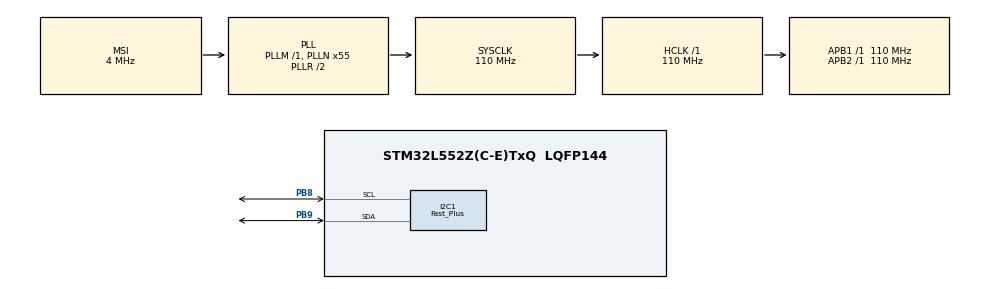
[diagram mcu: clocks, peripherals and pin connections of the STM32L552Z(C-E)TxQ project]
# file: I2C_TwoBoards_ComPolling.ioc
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I2C1.AddressingMode=I2C_ADDRESSINGMODE_10BIT
I2C1.Analog_Filter=I2C_ANALOGFILTER_ENABLE
I2C1.DualAddressMode=I2C_DUALADDRESS_DISABLE
I2C1.GeneralCallMode=I2C_GENERALCALL_DISABLE
I2C1.I2C_Coeff_DF=0
I2C1.I2C_Fall_Time=2
I2C1.I2C_Rise_Time=26
I2C1.I2C_Speed_Mode=I2C_Fast_Plus
I2C1.NoStretchMode=I2C_NOSTRETCH_DISABLE
I2C1.OwnAddress=I2C_ADDRESS
I2C1.Speed=1000
I2C1.Timing=0x00801644
Mcu.Family=STM32L5
Mcu.Name=STM32L552Z(C-E)TxQ
Mcu.Package=LQFP144
Mcu.UserConstants=I2C_ADDRESS,0x30F
NVIC.PriorityGroup=NVIC_PRIORITYGROUP_3
PB8.GPIO_Pu=GPIO_PULLUP
PB8.Mode=I2C
PB8.Signal=I2C1_SCL
PB9.GPIO_Pu=GPIO_PULLUP
PB9.Mode=I2C
PB9.Signal=I2C1_SDA
ProjectManager.HeapSize=0x200
ProjectManager.StackSize=0x400
ProjectManager.TargetToolchain=EWARM V8.32
RCC.ADCCLockSelection=RCC_ADCCLKSOURCE_SYSCLK
RCC.ADCFreq_Value=110000000
RCC.AHBFreq_Value=110000000
RCC.APB1Freq_Value=110000000
RCC.APB1TimFreq_Value=110000000
RCC.APB2Freq_Value=110000000
RCC.APB2TimFreq_Value=110000000
RCC.CK48CLockSelection=RCC_USBCLKSOURCE_MSI
RCC.CortexFreq_Value=110000000
RCC.DATA_CACHE_ENABLE=0
RCC.HCLKFreq_Value=110000000
RCC.HSE_VALUE=16000000
RCC.HSI48_VALUE=48000000
RCC.HSI_VALUE=16000000
RCC.I2C1CLockSelection=RCC_I2C1CLKSOURCE_SYSCLK
RCC.I2C3CLockSelection=RCC_I2C3CLKSOURCE_HSI
RCC.INSTRUCTION_CACHE_ENABLE=0
RCC.LPTIM1CLockSelectionVirtual=RCC_LPTIM1CLKSOURCE_LSE
RCC.LSE_VALUE=32768
RCC.MSI_VALUE=4000000
RCC.PLLN=55
RCC.PLLSAI1N=24
RCC.RTCClockSelection=RCC_RTCCLKSOURCE_LSE
RCC.SYSCLKFreq_VALUE=110000000
RCC.SYSCLKSource=RCC_SYSCLKSOURCE_PLLCLK
RCC.USBFreq_Value=4000000
RCC.VCOOutputFreq_Value=220000000
VP_ICACHE_VS_ICACHE.Mode=DirectMappedCache
VP_PWR_VS_DBSignals.Mode=DisableDeadBatterySignals
board=custom

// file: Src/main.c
/* USER CODE BEGIN Header */
/**
  ******************************************************************************
  * @file    I2C/I2C_TwoBoards_ComPolling/Src/main.c
  * @author  MCD Application Team
  * @brief   This sample code shows how to use STM32L5xx I2C HAL API to transmit
  *          and receive a data buffer with a communication process based on
  *          Polling transfer.
  *          The communication is done using 2 Boards.
  ******************************************************************************
  * @attention
  *
  * Copyright (c) 2019 STMicroelectronics.
  * All rights reserved.
  *
  * This software is licensed under terms that can be found in the LICENSE file
  * in the root directory of this software component.
  * If no LICENSE file comes with this software, it is provided AS-IS.
  *
  ******************************************************************************
  */
/* USER CODE END Header */
#include "main.h"

/* USER CODE BEGIN PD */
/* Uncomment this line to use the board as master, if not it is used as slave */
//#define MASTER_BOARD
/* USER CODE END PD */

I2C_HandleTypeDef hi2c1;

/* USER CODE BEGIN PV */
/* Private variables ---------------------------------------------------------*/
/* Buffer used for transmission */
uint8_t aTxBuffer[] = " ****I2C_TwoBoards communication based on Polling****  ****I2C_TwoBoards communication based on Polling****  ****I2C_TwoBoards communication based on Polling**** ";

/* Buffer used for reception */
uint8_t aRxBuffer[RXBUFFERSIZE];
/* USER CODE END PV */

void SystemClock_Config(void);
static void MX_GPIO_Init(void);
static void MX_ICACHE_Init(void);
static void MX_I2C1_Init(void);
/* USER CODE BEGIN PFP */
/* Private function prototypes -----------------------------------------------*/
static uint16_t Buffercmp(uint8_t *pBuffer1, uint8_t *pBuffer2, uint16_t BufferLength);

/* USER CODE END PFP */

int main(void)
{

  /* USER CODE BEGIN 1 */
  /* STM32L5xx HAL library initialization:
       - Systick timer is configured by default as source of time base, but user
         can eventually implement his proper time base source (a general purpose
         timer for example or other time source), keeping in mind that Time base
         duration should be kept 1ms since PPP_TIMEOUT_VALUEs are defined and
         handled in milliseconds basis.
       - Set NVIC Group Priority to 3
       - Low Level Initialization
     */
  /* USER CODE END 1 */

  /* MCU Configuration--------------------------------------------------------*/

  /* Reset of all peripherals, Initializes the Flash interface and the Systick. */
  HAL_Init();

  /* Configure the system clock */
  SystemClock_Config();

  /* Initialize all configured peripherals */
  MX_GPIO_Init();
  MX_ICACHE_Init();
  MX_I2C1_Init();
  /* USER CODE BEGIN 2 */
  /* Configure LED2 and LED3 */
  BSP_LED_Init(LED2);
  BSP_LED_Init(LED3);

#ifdef MASTER_BOARD

  /* Configure User push-button */
  BSP_PB_Init(BUTTON_USER, BUTTON_MODE_GPIO);
  /* USER CODE END 2 */

  /* Infinite loop */
  /* USER CODE BEGIN WHILE */
  /* Wait for User push-button press before starting the Communication */
  while (BSP_PB_GetState(BUTTON_USER) != GPIO_PIN_SET)
  {
  }

  /* Delay to avoid that possible signal rebound is taken as button release */
  HAL_Delay(50);

  /* Wait for User push-button release before starting the Communication */
  while (BSP_PB_GetState(BUTTON_USER) != GPIO_PIN_RESET)
  {
  }

  /* The board sends the message and expects to receive it back */

  /*##- Start the transmission process #####################################*/
  /* While the I2C in reception process, user can transmit data through
     "aTxBuffer" buffer */
  /* Timeout is set to 10S */
  while (HAL_I2C_Master_Transmit(&hi2c1, (uint16_t)I2C_ADDRESS, (uint8_t *)aTxBuffer, TXBUFFERSIZE, 10000) != HAL_OK)
  {
    /* Error_Handler() function is called when Timeout error occurs.
       When Acknowledge failure occurs (Slave don't acknowledge its address)
       Master restarts communication */
    if (HAL_I2C_GetError(&hi2c1) != HAL_I2C_ERROR_AF)
    {
      Error_Handler();
    }
  }

  /* Turn LED2 on: Transfer in Transmission process is correct */
  BSP_LED_On(LED2);

  /* Wait for User push-button press before starting the Communication */
  while (BSP_PB_GetState(BUTTON_USER) != GPIO_PIN_SET)
  {
  }

  /* Delay to avoid that possible signal rebound is taken as button release */
  HAL_Delay(50);

  /* Wait for User push-button release before starting the Communication */
  while (BSP_PB_GetState(BUTTON_USER) != GPIO_PIN_RESET)
  {
  }

  /*##- Put I2C peripheral in reception process ############################*/
  /* Timeout is set to 10S */
  while (HAL_I2C_Master_Receive(&hi2c1, (uint16_t)I2C_ADDRESS, (uint8_t *)aRxBuffer, RXBUFFERSIZE, 10000) != HAL_OK)
  {
    /* Error_Handler() function is called when Timeout error occurs.
       When Acknowledge failure occurs (Slave don't acknowledge it's address)
       Master restarts communication */
    if (HAL_I2C_GetError(&hi2c1) != HAL_I2C_ERROR_AF)
    {
      Error_Handler();
    }
  }

  /* Turn LED2 off: Transfer in reception process is correct */
  BSP_LED_Off(LED2);

#else

  /* The board receives the message and sends it back */

  /*##- Put I2C peripheral in reception process ###########################*/
  /* Timeout is set to 10S  */
  if (HAL_I2C_Slave_Receive(&hi2c1, (uint8_t *)aRxBuffer, RXBUFFERSIZE, 10000) != HAL_OK)
  {
    /* Transfer error in reception process */
    Error_Handler();
  }

  /* Turn LED2 on: Transfer in reception process is correct */
  BSP_LED_On(LED2);

  /*##- Start the transmission process #####################################*/
  /* While the I2C in reception process, user can transmit data through
     "aTxBuffer" buffer */
  /* Timeout is set to 10S */
  if (HAL_I2C_Slave_Transmit(&hi2c1, (uint8_t *)aTxBuffer, TXBUFFERSIZE, 10000) != HAL_OK)
  {
    /* Transfer error in transmission process */
    Error_Handler();
  }

  /* Turn LED2 off: Transfer in transmission process is correct */
  BSP_LED_Off(LED2);

#endif /* MASTER_BOARD */

  /*##- Compare the sent and received buffers ##############################*/
  if (Buffercmp((uint8_t *)aTxBuffer, (uint8_t *)aRxBuffer, RXBUFFERSIZE))
  {
    /* Processing Error */
    Error_Handler();
  }

  /* Infinite loop */
  while (1)
  {
    /* USER CODE END WHILE */

  }
}

void SystemClock_Config(void)
{
  RCC_OscInitTypeDef RCC_OscInitStruct = {0};
  RCC_ClkInitTypeDef RCC_ClkInitStruct = {0};

  /** Configure the main internal regulator output voltage
  */
  if (HAL_PWREx_ControlVoltageScaling(PWR_REGULATOR_VOLTAGE_SCALE0) != HAL_OK)
  {
    Error_Handler();
  }

  /** Initializes the RCC Oscillators according to the specified parameters
  * in the RCC_OscInitTypeDef structure.
  */
  RCC_OscInitStruct.OscillatorType = RCC_OSCILLATORTYPE_MSI;
  RCC_OscInitStruct.MSIState = RCC_MSI_ON;
  RCC_OscInitStruct.MSICalibrationValue = RCC_MSICALIBRATION_DEFAULT;
  RCC_OscInitStruct.MSIClockRange = RCC_MSIRANGE_6;
  RCC_OscInitStruct.PLL.PLLState = RCC_PLL_ON;
  RCC_OscInitStruct.PLL.PLLSource = RCC_PLLSOURCE_MSI;
  RCC_OscInitStruct.PLL.PLLM = 1;
  RCC_OscInitStruct.PLL.PLLN = 55;
  RCC_OscInitStruct.PLL.PLLP = RCC_PLLP_DIV7;
  RCC_OscInitStruct.PLL.PLLQ = RCC_PLLQ_DIV2;
  RCC_OscInitStruct.PLL.PLLR = RCC_PLLR_DIV2;
  if (HAL_RCC_OscConfig(&RCC_OscInitStruct) != HAL_OK)
  {
    Error_Handler();
  }

  /** Initializes the CPU, AHB and APB buses clocks
  */
  RCC_ClkInitStruct.ClockType = RCC_CLOCKTYPE_HCLK|RCC_CLOCKTYPE_SYSCLK
                              |RCC_CLOCKTYPE_PCLK1|RCC_CLOCKTYPE_PCLK2;
  RCC_ClkInitStruct.SYSCLKSource = RCC_SYSCLKSOURCE_PLLCLK;
  RCC_ClkInitStruct.AHBCLKDivider = RCC_SYSCLK_DIV1;
  RCC_ClkInitStruct.APB1CLKDivider = RCC_HCLK_DIV1;
  RCC_ClkInitStruct.APB2CLKDivider = RCC_HCLK_DIV1;

  if (HAL_RCC_ClockConfig(&RCC_ClkInitStruct, FLASH_LATENCY_5) != HAL_OK)
  {
    Error_Handler();
  }
}

static void MX_I2C1_Init(void)
{

  hi2c1.Instance = I2C1;
  hi2c1.Init.Timing = 0x00801644;
  hi2c1.Init.OwnAddress1 = I2C_ADDRESS;
  hi2c1.Init.AddressingMode = I2C_ADDRESSINGMODE_10BIT;
  hi2c1.Init.DualAddressMode = I2C_DUALADDRESS_DISABLE;
  hi2c1.Init.OwnAddress2 = 0;
  hi2c1.Init.OwnAddress2Masks = I2C_OA2_NOMASK;
  hi2c1.Init.GeneralCallMode = I2C_GENERALCALL_DISABLE;
  hi2c1.Init.NoStretchMode = I2C_NOSTRETCH_DISABLE;
  if (HAL_I2C_Init(&hi2c1) != HAL_OK)
  {
    Error_Handler();
  }

  /** Configure Analogue filter
  */
  if (HAL_I2CEx_ConfigAnalogFilter(&hi2c1, I2C_ANALOGFILTER_ENABLE) != HAL_OK)
  {
    Error_Handler();
  }

  /** Configure Digital filter
  */
  if (HAL_I2CEx_ConfigDigitalFilter(&hi2c1, 0) != HAL_OK)
  {
    Error_Handler();
  }

  /** I2C Fast mode Plus enable
  */
  HAL_I2CEx_EnableFastModePlus(I2C_FASTMODEPLUS_I2C1);

}

static void MX_ICACHE_Init(void)
{

  /** Enable instruction cache in 1-way (direct mapped cache)
  */
  if (HAL_ICACHE_ConfigAssociativityMode(ICACHE_1WAY) != HAL_OK)
  {
    Error_Handler();
  }
  if (HAL_ICACHE_Enable() != HAL_OK)
  {
    Error_Handler();
  }

}

static void MX_GPIO_Init(void)
{

  /* GPIO Ports Clock Enable */
  __HAL_RCC_GPIOB_CLK_ENABLE();

}

/* USER CODE BEGIN 4 */
/**
  * @brief  Compares two buffers.
  * @param  pBuffer1, pBuffer2: buffers to be compared.
  * @param  BufferLength: buffer's length
  * @retval 0  : pBuffer1 identical to pBuffer2
  *         >0 : pBuffer1 differs from pBuffer2
  */
static uint16_t Buffercmp(uint8_t *pBuffer1, uint8_t *pBuffer2, uint16_t BufferLength)
{
  while (BufferLength--)
  {
    if ((*pBuffer1) != *pBuffer2)
    {
      return BufferLength;
    }
    pBuffer1++;
    pBuffer2++;
  }

  return 0;
}

/* USER CODE END 4 */

void Error_Handler(void)
{
  /* USER CODE BEGIN Error_Handler_Debug */
  /* Turn LED3 on */
  BSP_LED_On(LED3);
  while (1)
  {
  }
  /* USER CODE END Error_Handler_Debug */
}

#ifdef  USE_FULL_ASSERT
/**
  * @brief  Reports the name of the source file and the source line number
  *         where the assert_param error has occurred.
  * @param  file: pointer to the source file name
  * @param  line: assert_param error line source number
  * @retval None
  */
void assert_failed(uint8_t *file, uint32_t line)
{
  /* USER CODE BEGIN 6 */
  /* User can add his own implementation to report the file name and line number,
     ex: printf("Wrong parameters value: file %s on line %d\r\n", file, line) */
  Error_Handler();
  /* USER CODE END 6 */
}
#endif /* USE_FULL_ASSERT */
